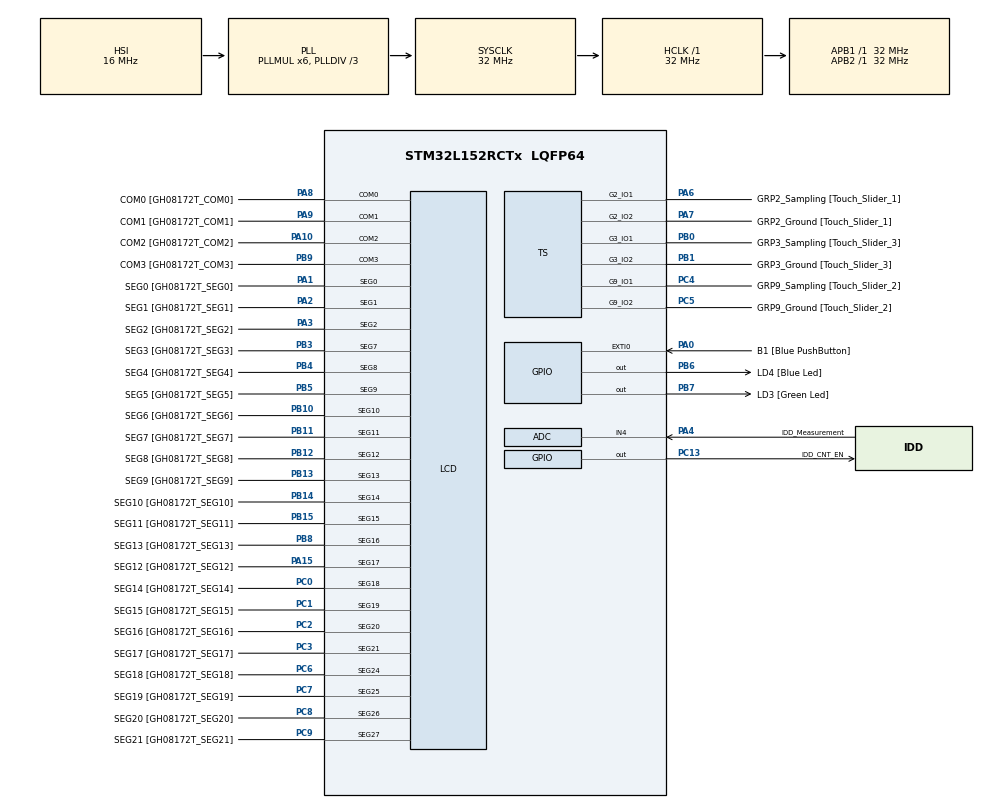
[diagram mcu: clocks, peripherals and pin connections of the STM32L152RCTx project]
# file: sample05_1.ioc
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ADC.Channel=ADC_CHANNEL_4
ADC.Channel-0\#ChannelRegularConversion=ADC_CHANNEL_4
ADC.Channel-IN4=ADC_CHANNEL_4
ADC.ExternalTrigConv=ADC_EXTERNALTRIGCONV_T2_CC3
ADC.ExternalTrigConv-0\#ChannelRegularConversion=ADC_SOFTWARE_START
ADC.ExternalTrigConvEdge=ADC_EXTERNALTRIGCONVEDGE_RISING
ADC.Rank-0\#ChannelRegularConversion=1
ADC.SamplingTime-0\#ChannelRegularConversion=ADC_SAMPLETIME_4CYCLES
LCD.Bias=LCD_BIAS_1_3
LCD.PulseOnDuration=LCD_PULSEONDURATION_4
Mcu.Family=STM32L1
Mcu.Name=STM32L152RCTx
Mcu.Package=LQFP64
NVIC.PriorityGroup=NVIC_PRIORITYGROUP_0
PA0-WKUP1.GPIO_Label=B1 [Blue PushButton]
PA0-WKUP1.GPIO_ModeDefaultEXTI=GPIO_MODE_EVT_RISING
PA0-WKUP1.GPIO_PuPd=GPIO_NOPULL
PA0-WKUP1.Signal=GPXTI0
PA1.GPIO_Label=SEG0 [GH08172T_SEG0]
PA1.GPIO_Mode=GPIO_MODE_AF_PP
PA1.GPIO_PuPd=GPIO_NOPULL
PA1.GPIO_Speed=GPIO_SPEED_FREQ_LOW
PA1.Mode=SEG0
PA1.Signal=LCD_SEG0
PA10.GPIO_Label=COM2 [GH08172T_COM2]
PA10.GPIO_Mode=GPIO_MODE_AF_PP
PA10.GPIO_PuPd=GPIO_NOPULL
PA10.GPIO_Speed=GPIO_SPEED_FREQ_LOW
PA10.Mode=1/4 Duty Cycle
PA10.Signal=LCD_COM2
PA13.GPIO_Label=SWDIO
PA13.Mode=Serial_Wire
PA13.Signal=SYS_JTMS-SWDIO
PA14.GPIO_Label=SWCLK
PA14.Mode=Serial_Wire
PA14.Signal=SYS_JTCK-SWCLK
PA15.GPIO_Label=SEG12 [GH08172T_SEG12]
PA15.GPIO_Mode=GPIO_MODE_AF_PP
PA15.GPIO_PuPd=GPIO_NOPULL
PA15.GPIO_Speed=GPIO_SPEED_FREQ_LOW
PA15.Mode=SEG17
PA15.Signal=LCD_SEG17
PA2.GPIO_Label=SEG1 [GH08172T_SEG1]
PA2.GPIO_Mode=GPIO_MODE_AF_PP
PA2.GPIO_PuPd=GPIO_NOPULL
PA2.GPIO_Speed=GPIO_SPEED_FREQ_LOW
PA2.Mode=SEG1
PA2.Signal=LCD_SEG1
PA3.GPIO_Label=SEG2 [GH08172T_SEG2]
PA3.GPIO_Mode=GPIO_MODE_AF_PP
PA3.GPIO_PuPd=GPIO_NOPULL
PA3.GPIO_Speed=GPIO_SPEED_FREQ_LOW
PA3.Mode=SEG2
PA3.Signal=LCD_SEG2
PA4.GPIO_Label=IDD_Measurement
PA4.GPIO_Mode=GPIO_MODE_ANALOG
PA4.GPIO_PuPd=GPIO_NOPULL
PA4.Mode=IN4
PA4.Signal=ADC_IN4
PA6.GPIO_Label=GRP2_Sampling [Touch_Slider_1]
PA6.Mode=G2_IO1-Sampling
PA6.Signal=TS_G2_IO1
PA7.GPIO_Label=GRP2_Ground [Touch_Slider_1]
PA7.Mode=G2_IO2-Channel
PA7.Signal=TS_G2_IO2
PA8.GPIO_Label=COM0 [GH08172T_COM0]
PA8.GPIO_Mode=GPIO_MODE_AF_PP
PA8.GPIO_PuPd=GPIO_NOPULL
PA8.GPIO_Speed=GPIO_SPEED_FREQ_LOW
PA8.Mode=1/4 Duty Cycle
PA8.Signal=LCD_COM0
PA9.GPIO_Label=COM1 [GH08172T_COM1]
PA9.GPIO_Mode=GPIO_MODE_AF_PP
PA9.GPIO_PuPd=GPIO_NOPULL
PA9.GPIO_Speed=GPIO_SPEED_FREQ_LOW
PA9.Mode=1/4 Duty Cycle
PA9.Signal=LCD_COM1
PB0.GPIO_Label=GRP3_Sampling [Touch_Slider_3]
PB0.Mode=G3_IO1-Sampling
PB0.Signal=TS_G3_IO1
PB1.GPIO_Label=GRP3_Ground [Touch_Slider_3]
PB1.Mode=G3_IO2-Channel
PB1.Signal=TS_G3_IO2
PB10.GPIO_Label=SEG6 [GH08172T_SEG6]
PB10.GPIO_Mode=GPIO_MODE_AF_PP
PB10.GPIO_PuPd=GPIO_NOPULL
PB10.GPIO_Speed=GPIO_SPEED_FREQ_LOW
PB10.Mode=SEG10
PB10.Signal=LCD_SEG10
PB11.GPIO_Label=SEG7 [GH08172T_SEG7]
PB11.GPIO_Mode=GPIO_MODE_AF_PP
PB11.GPIO_PuPd=GPIO_NOPULL
PB11.GPIO_Speed=GPIO_SPEED_FREQ_LOW
PB11.Mode=SEG11
PB11.Signal=LCD_SEG11
PB12.GPIO_Label=SEG8 [GH08172T_SEG8]
PB12.GPIO_Mode=GPIO_MODE_AF_PP
PB12.GPIO_PuPd=GPIO_NOPULL
PB12.GPIO_Speed=GPIO_SPEED_FREQ_LOW
PB12.Mode=SEG12
PB12.Signal=LCD_SEG12
PB13.GPIO_Label=SEG9 [GH08172T_SEG9]
PB13.GPIO_Mode=GPIO_MODE_AF_PP
PB13.GPIO_PuPd=GPIO_NOPULL
PB13.GPIO_Speed=GPIO_SPEED_FREQ_LOW
PB13.Mode=SEG13
PB13.Signal=LCD_SEG13
PB14.GPIO_Label=SEG10 [GH08172T_SEG10]
PB14.GPIO_Mode=GPIO_MODE_AF_PP
PB14.GPIO_PuPd=GPIO_NOPULL
PB14.GPIO_Speed=GPIO_SPEED_FREQ_LOW
PB14.Mode=SEG14
PB14.Signal=LCD_SEG14
PB15.GPIO_Label=SEG11 [GH08172T_SEG11]
PB15.GPIO_Mode=GPIO_MODE_AF_PP
PB15.GPIO_PuPd=GPIO_NOPULL
PB15.GPIO_Speed=GPIO_SPEED_FREQ_LOW
PB15.Mode=SEG15
PB15.Signal=LCD_SEG15
PB3.GPIO_Label=SEG3 [GH08172T_SEG3]
PB3.GPIO_Mode=GPIO_MODE_AF_PP
PB3.GPIO_PuPd=GPIO_NOPULL
PB3.GPIO_Speed=GPIO_SPEED_FREQ_LOW
PB3.Mode=SEG7
PB3.Signal=LCD_SEG7
PB4.GPIO_Label=SEG4 [GH08172T_SEG4]
PB4.GPIO_Mode=GPIO_MODE_AF_PP
PB4.GPIO_PuPd=GPIO_NOPULL
PB4.GPIO_Speed=GPIO_SPEED_FREQ_LOW
PB4.Mode=SEG8
PB4.Signal=LCD_SEG8
PB5.GPIO_Label=SEG5 [GH08172T_SEG5]
PB5.GPIO_Mode=GPIO_MODE_AF_PP
PB5.GPIO_PuPd=GPIO_NOPULL
PB5.GPIO_Speed=GPIO_SPEED_FREQ_LOW
PB5.Mode=SEG9
PB5.Signal=LCD_SEG9
PB6.GPIO_Label=LD4 [Blue Led]
PB6.GPIO_ModeDefaultOutputPP=GPIO_MODE_OUTPUT_PP
PB6.GPIO_PuPd=GPIO_NOPULL
PB6.GPIO_Speed=GPIO_SPEED_FREQ_LOW
PB6.Signal=GPIO_Output
PB7.GPIO_Label=LD3 [Green Led]
PB7.GPIO_ModeDefaultOutputPP=GPIO_MODE_OUTPUT_PP
PB7.GPIO_PuPd=GPIO_NOPULL
PB7.GPIO_Speed=GPIO_SPEED_FREQ_LOW
PB7.Signal=GPIO_Output
PB8.GPIO_Label=SEG13 [GH08172T_SEG13]
PB8.GPIO_Mode=GPIO_MODE_AF_PP
PB8.GPIO_PuPd=GPIO_NOPULL
PB8.GPIO_Speed=GPIO_SPEED_FREQ_LOW
PB8.Mode=SEG16
PB8.Signal=LCD_SEG16
PB9.GPIO_Label=COM3 [GH08172T_COM3]
PB9.GPIO_Mode=GPIO_MODE_AF_PP
PB9.GPIO_PuPd=GPIO_NOPULL
PB9.GPIO_Speed=GPIO_SPEED_FREQ_LOW
PB9.Mode=1/4 Duty Cycle
PB9.Signal=LCD_COM3
PC0.GPIO_Label=SEG14 [GH08172T_SEG14]
PC0.GPIO_Mode=GPIO_MODE_AF_PP
PC0.GPIO_PuPd=GPIO_NOPULL
PC0.GPIO_Speed=GPIO_SPEED_FREQ_LOW
PC0.Mode=SEG18
PC0.Signal=LCD_SEG18
PC1.GPIO_Label=SEG15 [GH08172T_SEG15]
PC1.GPIO_Mode=GPIO_MODE_AF_PP
PC1.GPIO_PuPd=GPIO_NOPULL
PC1.GPIO_Speed=GPIO_SPEED_FREQ_LOW
PC1.Mode=SEG19
PC1.Signal=LCD_SEG19
PC10.GPIO_Label=SEG22 [GH08172T_SEG22]
PC10.GPIO_Mode=GPIO_MODE_AF_PP
PC10.GPIO_PuPd=GPIO_NOPULL
PC10.GPIO_Speed=GPIO_SPEED_FREQ_LOW
PC10.Signal=LCD_SEG28
PC11.GPIO_Label=SEG23 [GH08172T_SEG23]
PC11.GPIO_Mode=GPIO_MODE_AF_PP
PC11.GPIO_PuPd=GPIO_NOPULL
PC11.GPIO_Speed=GPIO_SPEED_FREQ_LOW
PC11.Signal=LCD_SEG29
PC13-WKUP2.GPIO_Label=IDD_CNT_EN
PC13-WKUP2.PinState=GPIO_PIN_SET
PC13-WKUP2.Signal=GPIO_Output
PC14-OSC32_IN.GPIO_Label=PC14-OSC32_IN
PC14-OSC32_IN.Mode=LSE-External-Oscillator
PC14-OSC32_IN.Signal=RCC_OSC32_IN
PC15-OSC32_OUT.GPIO_Label=PC15-OSC32_OUT
PC15-OSC32_OUT.Mode=LSE-External-Oscillator
PC15-OSC32_OUT.Signal=RCC_OSC32_OUT
PC2.GPIO_Label=SEG16 [GH08172T_SEG16]
PC2.GPIO_Mode=GPIO_MODE_AF_PP
PC2.GPIO_PuPd=GPIO_NOPULL
PC2.GPIO_Speed=GPIO_SPEED_FREQ_LOW
PC2.Mode=SEG20
PC2.Signal=LCD_SEG20
PC3.GPIO_Label=SEG17 [GH08172T_SEG17]
PC3.GPIO_Mode=GPIO_MODE_AF_PP
PC3.GPIO_PuPd=GPIO_NOPULL
PC3.GPIO_Speed=GPIO_SPEED_FREQ_LOW
PC3.Mode=SEG21
PC3.Signal=LCD_SEG21
PC4.GPIO_Label=GRP9_Sampling [Touch_Slider_2]
PC4.Mode=G9_IO1-Sampling
PC4.Signal=TS_G9_IO1
PC5.GPIO_Label=GRP9_Ground [Touch_Slider_2]
PC5.Mode=G9_IO2-Channel
PC5.Signal=TS_G9_IO2
PC6.GPIO_Label=SEG18 [GH08172T_SEG18]
PC6.GPIO_Mode=GPIO_MODE_AF_PP
PC6.GPIO_PuPd=GPIO_NOPULL
PC6.GPIO_Speed=GPIO_SPEED_FREQ_LOW
PC6.Mode=SEG24
PC6.Signal=LCD_SEG24
PC7.GPIO_Label=SEG19 [GH08172T_SEG19]
PC7.GPIO_Mode=GPIO_MODE_AF_PP
PC7.GPIO_PuPd=GPIO_NOPULL
PC7.GPIO_Speed=GPIO_SPEED_FREQ_LOW
PC7.Mode=SEG25
PC7.Signal=LCD_SEG25
PC8.GPIO_Label=SEG20 [GH08172T_SEG20]
PC8.GPIO_Mode=GPIO_MODE_AF_PP
PC8.GPIO_PuPd=GPIO_NOPULL
PC8.GPIO_Speed=GPIO_SPEED_FREQ_LOW
PC8.Mode=SEG26
PC8.Signal=LCD_SEG26
PC9.GPIO_Label=SEG21 [GH08172T_SEG21]
PC9.GPIO_Mode=GPIO_MODE_AF_PP
PC9.GPIO_PuPd=GPIO_NOPULL
PC9.GPIO_Speed=GPIO_SPEED_FREQ_LOW
PC9.Mode=SEG27
PC9.Signal=LCD_SEG27
ProjectManager.HeapSize=0x200
ProjectManager.StackSize=0x400
ProjectManager.TargetToolchain=TrueSTUDIO
RCC.48MHZClocksFreq_Value=48000000
RCC.AHBFreq_Value=32000000
RCC.APB1Freq_Value=32000000
RCC.APB1TimFreq_Value=32000000
RCC.APB2Freq_Value=32000000
RCC.APB2TimFreq_Value=32000000
RCC.HCLKFreq_Value=32000000
RCC.HSE_VALUE=8000000
RCC.HSI_VALUE=16000000
RCC.MSI_VALUE=2097000
RCC.PLLDIV=RCC_PLL_DIV3
RCC.PLLMUL=RCC_PLL_MUL6
RCC.RTCClockSelectionVirtual=RCC_RTCCLKSOURCE_LSE
RCC.SYSCLKFreq_VALUE=32000000
RCC.SYSCLKSource=RCC_SYSCLKSOURCE_PLLCLK
RCC.USBOutput=48000000
RCC.VCOOutputFreq_Value=96000000
VP_LCD_LCD_mux.Mode=Multiplex
VP_RTC_VS_RTC_Activate.Mode=RTC_Enabled
board=32L152CDISCOVERY

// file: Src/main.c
/* USER CODE BEGIN Header */
/**
  ******************************************************************************
  * @file           : main.c
  * @brief          : Main program body
  ******************************************************************************
  ** This notice applies to any and all portions of this file
  * that are not between comment pairs USER CODE BEGIN and
  * USER CODE END. Other portions of this file, whether
  * inserted by the user or by software development tools
  * are owned by their respective copyright owners.
  *
  * COPYRIGHT(c) 2019 STMicroelectronics
  *
  * Redistribution and use in source and binary forms, with or without modification,
  * are permitted provided that the following conditions are met:
  *   1. Redistributions of source code must retain the above copyright notice,
  *      this list of conditions and the following disclaimer.
  *   2. Redistributions in binary form must reproduce the above copyright notice,
  *      this list of conditions and the following disclaimer in the documentation
  *      and/or other materials provided with the distribution.
  *   3. Neither the name of STMicroelectronics nor the names of its contributors
  *      may be used to endorse or promote products derived from this software
  *      without specific prior written permission.
  *
  * THIS SOFTWARE IS PROVIDED BY THE COPYRIGHT HOLDERS AND CONTRIBUTORS "AS IS"
  * AND ANY EXPRESS OR IMPLIED WARRANTIES, INCLUDING, BUT NOT LIMITED TO, THE
  * IMPLIED WARRANTIES OF MERCHANTABILITY AND FITNESS FOR A PARTICULAR PURPOSE ARE
  * DISCLAIMED. IN NO EVENT SHALL THE COPYRIGHT HOLDER OR CONTRIBUTORS BE LIABLE
  * FOR ANY DIRECT, INDIRECT, INCIDENTAL, SPECIAL, EXEMPLARY, OR CONSEQUENTIAL
  * DAMAGES (INCLUDING, BUT NOT LIMITED TO, PROCUREMENT OF SUBSTITUTE GOODS OR
  * SERVICES; LOSS OF USE, DATA, OR PROFITS; OR BUSINESS INTERRUPTION) HOWEVER
  * CAUSED AND ON ANY THEORY OF LIABILITY, WHETHER IN CONTRACT, STRICT LIABILITY,
  * OR TORT (INCLUDING NEGLIGENCE OR OTHERWISE) ARISING IN ANY WAY OUT OF THE USE
  * OF THIS SOFTWARE, EVEN IF ADVISED OF THE POSSIBILITY OF SUCH DAMAGE.
  *
  ******************************************************************************
  */
/* USER CODE END Header */

#include "main.h"

/* USER CODE BEGIN Includes */
#include "lcd.h"
/* USER CODE END Includes */

ADC_HandleTypeDef hadc;

LCD_HandleTypeDef hlcd;

RTC_HandleTypeDef hrtc;

void SystemClock_Config(void);
static void MX_GPIO_Init(void);
static void MX_ADC_Init(void);
static void MX_LCD_Init(void);
static void MX_TS_Init(void);
static void MX_RTC_Init(void);

int main(void)
{

  /* MCU Configuration--------------------------------------------------------*/

  /* Reset of all peripherals, Initializes the Flash interface and the Systick. */
  HAL_Init();

  /* Configure the system clock */
  SystemClock_Config();

  /* Initialize all configured peripherals */
  MX_GPIO_Init();
  MX_ADC_Init();
  MX_LCD_Init();
  MX_TS_Init();
  MX_RTC_Init();
  /* USER CODE BEGIN 2 */
LCD_WriteChar(1, '1');
LCD_WriteChar(2, '2');
LCD_WriteChar(3, '3');
LCD_WriteChar(4, '4');
LCD_WriteChar(5, '5');
LCD_WriteChar(6, '6');
  /* USER CODE END 2 */

  /* Infinite loop */
  while (1)
  {

  }
}

void SystemClock_Config(void)
{
  RCC_OscInitTypeDef RCC_OscInitStruct = {0};
  RCC_ClkInitTypeDef RCC_ClkInitStruct = {0};
  RCC_PeriphCLKInitTypeDef PeriphClkInit = {0};

  /**Configure the main internal regulator output voltage
  */
  __HAL_PWR_VOLTAGESCALING_CONFIG(PWR_REGULATOR_VOLTAGE_SCALE1);
  /**Initializes the CPU, AHB and APB busses clocks
  */
  RCC_OscInitStruct.OscillatorType = RCC_OSCILLATORTYPE_HSI|RCC_OSCILLATORTYPE_LSE;
  RCC_OscInitStruct.LSEState = RCC_LSE_ON;
  RCC_OscInitStruct.HSIState = RCC_HSI_ON;
  RCC_OscInitStruct.HSICalibrationValue = RCC_HSICALIBRATION_DEFAULT;
  RCC_OscInitStruct.PLL.PLLState = RCC_PLL_ON;
  RCC_OscInitStruct.PLL.PLLSource = RCC_PLLSOURCE_HSI;
  RCC_OscInitStruct.PLL.PLLMUL = RCC_PLL_MUL6;
  RCC_OscInitStruct.PLL.PLLDIV = RCC_PLL_DIV3;
  if (HAL_RCC_OscConfig(&RCC_OscInitStruct) != HAL_OK)
  {
    Error_Handler();
  }
  /**Initializes the CPU, AHB and APB busses clocks
  */
  RCC_ClkInitStruct.ClockType = RCC_CLOCKTYPE_HCLK|RCC_CLOCKTYPE_SYSCLK
                              |RCC_CLOCKTYPE_PCLK1|RCC_CLOCKTYPE_PCLK2;
  RCC_ClkInitStruct.SYSCLKSource = RCC_SYSCLKSOURCE_PLLCLK;
  RCC_ClkInitStruct.AHBCLKDivider = RCC_SYSCLK_DIV1;
  RCC_ClkInitStruct.APB1CLKDivider = RCC_HCLK_DIV1;
  RCC_ClkInitStruct.APB2CLKDivider = RCC_HCLK_DIV1;

  if (HAL_RCC_ClockConfig(&RCC_ClkInitStruct, FLASH_LATENCY_1) != HAL_OK)
  {
    Error_Handler();
  }
  PeriphClkInit.PeriphClockSelection = RCC_PERIPHCLK_RTC|RCC_PERIPHCLK_LCD;
  PeriphClkInit.RTCClockSelection = RCC_RTCCLKSOURCE_LSE;
  PeriphClkInit.LCDClockSelection = RCC_RTCCLKSOURCE_LSE;

  if (HAL_RCCEx_PeriphCLKConfig(&PeriphClkInit) != HAL_OK)
  {
    Error_Handler();
  }
}

static void MX_ADC_Init(void)
{

  ADC_ChannelConfTypeDef sConfig = {0};

  /**Configure the global features of the ADC (Clock, Resolution, Data Alignment and number of conversion)
  */
  hadc.Instance = ADC1;
  hadc.Init.ClockPrescaler = ADC_CLOCK_ASYNC_DIV1;
  hadc.Init.Resolution = ADC_RESOLUTION_12B;
  hadc.Init.DataAlign = ADC_DATAALIGN_RIGHT;
  hadc.Init.ScanConvMode = ADC_SCAN_DISABLE;
  hadc.Init.EOCSelection = ADC_EOC_SEQ_CONV;
  hadc.Init.LowPowerAutoWait = ADC_AUTOWAIT_DISABLE;
  hadc.Init.LowPowerAutoPowerOff = ADC_AUTOPOWEROFF_DISABLE;
  hadc.Init.ChannelsBank = ADC_CHANNELS_BANK_A;
  hadc.Init.ContinuousConvMode = DISABLE;
  hadc.Init.NbrOfConversion = 1;
  hadc.Init.DiscontinuousConvMode = DISABLE;
  hadc.Init.ExternalTrigConv = ADC_EXTERNALTRIGCONV_T2_CC3;
  hadc.Init.ExternalTrigConvEdge = ADC_EXTERNALTRIGCONVEDGE_RISING;
  hadc.Init.DMAContinuousRequests = DISABLE;
  if (HAL_ADC_Init(&hadc) != HAL_OK)
  {
    Error_Handler();
  }
  /**Configure for the selected ADC regular channel its corresponding rank in the sequencer and its sample time.
  */
  sConfig.Channel = ADC_CHANNEL_4;
  sConfig.Rank = ADC_REGULAR_RANK_1;
  sConfig.SamplingTime = ADC_SAMPLETIME_4CYCLES;
  if (HAL_ADC_ConfigChannel(&hadc, &sConfig) != HAL_OK)
  {
    Error_Handler();
  }

}

static void MX_LCD_Init(void)
{

  hlcd.Instance = LCD;
  hlcd.Init.Prescaler = LCD_PRESCALER_1;
  hlcd.Init.Divider = LCD_DIVIDER_16;
  hlcd.Init.Duty = LCD_DUTY_1_4;
  hlcd.Init.Bias = LCD_BIAS_1_3;
  hlcd.Init.VoltageSource = LCD_VOLTAGESOURCE_INTERNAL;
  hlcd.Init.Contrast = LCD_CONTRASTLEVEL_0;
  hlcd.Init.DeadTime = LCD_DEADTIME_0;
  hlcd.Init.PulseOnDuration = LCD_PULSEONDURATION_4;
  hlcd.Init.MuxSegment = LCD_MUXSEGMENT_ENABLE;
  hlcd.Init.BlinkMode = LCD_BLINKMODE_OFF;
  hlcd.Init.BlinkFrequency = LCD_BLINKFREQUENCY_DIV8;
  if (HAL_LCD_Init(&hlcd) != HAL_OK)
  {
    Error_Handler();
  }

}

static void MX_RTC_Init(void)
{

  /**Initialize RTC Only
  */
  hrtc.Instance = RTC;
  hrtc.Init.HourFormat = RTC_HOURFORMAT_24;
  hrtc.Init.AsynchPrediv = 127;
  hrtc.Init.SynchPrediv = 255;
  hrtc.Init.OutPut = RTC_OUTPUT_DISABLE;
  hrtc.Init.OutPutPolarity = RTC_OUTPUT_POLARITY_HIGH;
  hrtc.Init.OutPutType = RTC_OUTPUT_TYPE_OPENDRAIN;
  if (HAL_RTC_Init(&hrtc) != HAL_OK)
  {
    Error_Handler();
  }

}

static void MX_TS_Init(void)
{

}

static void MX_GPIO_Init(void)
{
  GPIO_InitTypeDef GPIO_InitStruct = {0};

  /* GPIO Ports Clock Enable */
  __HAL_RCC_GPIOC_CLK_ENABLE();
  __HAL_RCC_GPIOA_CLK_ENABLE();
  __HAL_RCC_GPIOB_CLK_ENABLE();

  /*Configure GPIO pin Output Level */
  HAL_GPIO_WritePin(IDD_CNT_EN_GPIO_Port, IDD_CNT_EN_Pin, GPIO_PIN_SET);

  /*Configure GPIO pin Output Level */
  HAL_GPIO_WritePin(GPIOB, LD4_Pin|LD3_Pin, GPIO_PIN_RESET);

  /*Configure GPIO pin : IDD_CNT_EN_Pin */
  GPIO_InitStruct.Pin = IDD_CNT_EN_Pin;
  GPIO_InitStruct.Mode = GPIO_MODE_OUTPUT_PP;
  GPIO_InitStruct.Pull = GPIO_NOPULL;
  GPIO_InitStruct.Speed = GPIO_SPEED_FREQ_LOW;
  HAL_GPIO_Init(IDD_CNT_EN_GPIO_Port, &GPIO_InitStruct);

  /*Configure GPIO pin : B1_Pin */
  GPIO_InitStruct.Pin = B1_Pin;
  GPIO_InitStruct.Mode = GPIO_MODE_EVT_RISING;
  GPIO_InitStruct.Pull = GPIO_NOPULL;
  HAL_GPIO_Init(B1_GPIO_Port, &GPIO_InitStruct);

  /*Configure GPIO pins : LD4_Pin LD3_Pin */
  GPIO_InitStruct.Pin = LD4_Pin|LD3_Pin;
  GPIO_InitStruct.Mode = GPIO_MODE_OUTPUT_PP;
  GPIO_InitStruct.Pull = GPIO_NOPULL;
  GPIO_InitStruct.Speed = GPIO_SPEED_FREQ_LOW;
  HAL_GPIO_Init(GPIOB, &GPIO_InitStruct);

}

void Error_Handler(void)
{
}

/************************ (C) COPYRIGHT STMicroelectronics *****END OF FILE****/
